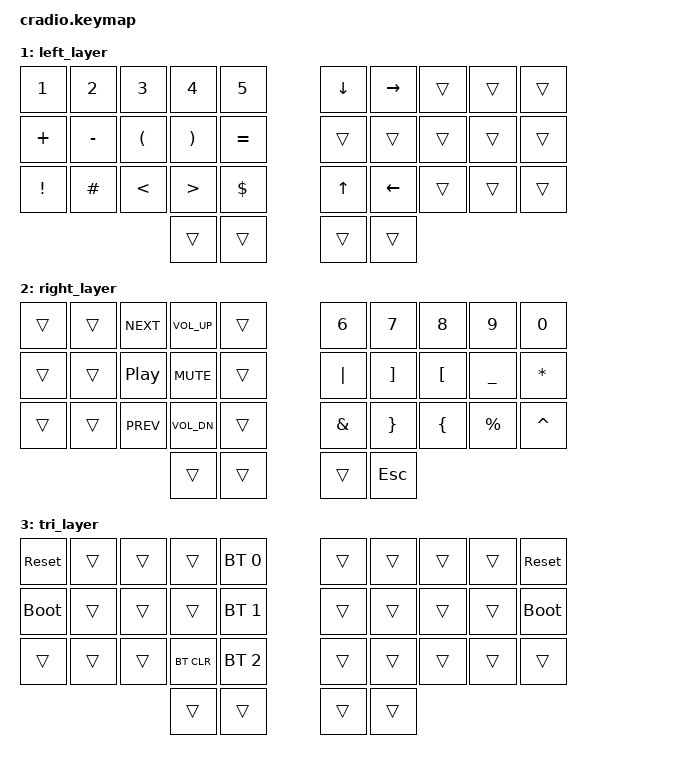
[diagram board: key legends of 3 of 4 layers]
// Copyright (c) 2022 The ZMK Contributors
// SPDX-License-Identifier: MIT

#include <behaviors.dtsi>
#include <dt-bindings/zmk/keys.h>
#include <dt-bindings/zmk/bt.h>

// Home row mods macro
#define HRML(k1,k2,k3,k4) &ht LGUI k1  &ht LALT k2  &ht LSHFT k3  &ht LCTRL k4
#define HRMR(k1,k2,k3,k4) &ht RCTRL k1  &ht RSHFT k2  &ht RALT k3  &ht RGUI k4

/ {
    behaviors {
        ht: hold_tap {
            label = "hold_tap";
            compatible = "zmk,behavior-hold-tap";
            #binding-cells = <2>;
            flavor = "tap-preferred";
            tapping-term-ms = <220>;
            quick-tap-ms = <75>;
            require-prior-idle-ms = <100>;
            bindings = <&kp>, <&kp>;
        };
    };

    conditional_layers {
        compatible = "zmk,conditional-layers";
        tri_layer {
            if-layers = <1 2>;
            then-layer = <3>;
        };
    };

    combos { 
        compatible = "zmk,combos";

        combo_esc {
            timeout-ms = <50>;
            key-positions = <0 31>;
            bindings = <&kp ESC>;
        };

        combo_bslh {
            timeout-ms = <50>;
            key-positions = <29 32>;
            bindings = <&kp BSLH>;
        };

        combo_btick {
            timeout-ms = <50>;
            key-positions = <20 31>;
            bindings = <&kp GRAVE>;
        };

        combo_quot {
            timeout-ms = <50>;
            key-positions = <19 32>;
            bindings = <&kp SQT>;
        };

        combo_at {
            timeout-ms = <25>;
            key-positions = <10 13>;
            bindings = <&kp AT>;
        };

    };

    keymap {
        compatible = "zmk,keymap";
        default_layer {
            bindings = <
        //╭──────────┬──────────┬──────────┬──────────┬──────────╮   ╭──────────┬──────────┬──────────┬──────────┬──────────╮
        //│  Q       │  W       │  F       │  P       │  B       │   │  J       │  L       │  U       │  Y       │  ;       │
            &kp Q      &kp W      &kp F      &kp P      &kp B          &kp J      &kp L      &kp U      &kp Y      &kp SEMI
        //├──────────┼──────────┼──────────┼──────────┼──────────┤   ├──────────┼──────────┼──────────┼──────────┼──────────┤
        //│  A       │  R       │  S       │  T       │  G       │   │  M       │  N       │  E       │  I       │  O       │
            HRML(A,        R,         S,         T)     &kp G          &kp M      HRMR(N,        E,         I,        O)
        //├──────────┼──────────┼──────────┼──────────┼──────────┤   ├──────────┼──────────┼──────────┼──────────┼──────────┤
        //│  Z       │  X       │  C       │  D       │  V       │   │  K       │  H       │ , <      │ . >      │ / ?      │
            &kp Z      &kp X      &kp C      &kp D      &kp V          &kp K      &kp H      &kp COMMA  &kp DOT    &kp FSLH
        //╰──────────┴──────────┴──────────┼──────────┼──────────┤   ├──────────┼──────────┼──────────┴──────────┴──────────╯
                                            &lt 2 TAB  &kp SPACE      &kp BSPC   &lt 1 ENTER
        //                                 ╰──────────┴──────────╯   ╰──────────┴──────────╯
            >;
        };

        left_layer {
            bindings = <
        //╭──────────┬──────────┬──────────┬──────────┬──────────╮   ╭──────────┬──────────┬──────────┬──────────┬──────────╮
        //│   1      │  2       │  3       │  4       │  5       │   │          │          │          │          │          │
            &kp N1    &kp N2     &kp N3     &kp N4     &kp N5         &kp DOWN   &kp RIGHT  &trans     &trans     &trans
        //├──────────┼──────────┼──────────┼──────────┼──────────┤   ├──────────┼──────────┼──────────┼──────────┼──────────┤
        //│  +       │  -       │  (       │  )       │  =       │   │          │          │          │          │          │
            &kp PLUS  &kp MINUS  &kp LPAR   &kp RPAR   &kp EQUAL      &trans     &trans     &trans     &trans     &trans
        //├──────────┼──────────┼──────────┼──────────┼──────────┤   ├──────────┼──────────┼──────────┼──────────┼──────────┤
        //│  !       │  #       │  <       │  >       │  $       │   │          │          │          │          │          │
            &kp EXCL   &kp HASH  &kp LT     &kp GT     &kp DLLR       &kp UP    &kp LEFT    &trans     &trans     &trans
        //╰──────────┴──────────┴──────────┼──────────┼──────────┤   ├──────────┼──────────┼──────────┴──────────┴──────────╯
                                             &trans     &trans        &trans     &trans
        //                                 ╰──────────┴──────────╯   ╰──────────┴──────────╯
            >;
        };

        right_layer {
            bindings = <
        //╭──────────┬──────────┬──────────┬──────────┬──────────╮   ╭──────────┬──────────┬──────────┬──────────┬──────────╮
        //│          │          │          │          │          │   │  6       │  7       │  8       │   9      │  0       │
           &trans     &trans     &kp C_NEXT &kp C_VOL_UP &trans       &kp N6     &kp N7     &kp N8     &kp N9    &kp N0
        //├──────────┼──────────┼──────────┼──────────┼──────────┤   ├──────────┼──────────┼──────────┼──────────┼──────────┤
        //│          │          │          │          │          │   │  |       │  ]       │  [       │  _       │  *       │
           &trans     &trans     &kp C_PP   &kp C_MUTE   &trans       &kp PIPE   &kp RBKT   &kp LBKT   &kp UNDER  &kp STAR
        //├──────────┼──────────┼──────────┼──────────┼──────────┤   ├──────────┼──────────┼──────────┼──────────┼──────────┤
        //│          │          │          │          │          │   │  &       │  }       │  {       │  %       │  ^       │
           &trans     &trans     &kp C_PREV &kp C_VOL_DN &trans       &kp AMPS   &kp RBRC   &kp LBRC   &kp PRCNT  &kp CARET
        //╰──────────┴──────────┴──────────┼──────────┼──────────┤   ├──────────┼──────────┼──────────┴──────────┴──────────╯
                                            &trans     &trans         &trans     &kp ESC
        //                                 ╰──────────┴──────────╯   ╰──────────┴──────────╯
            >;
        };

        tri_layer {
            bindings = <
        //╭──────────┬──────────┬──────────┬──────────┬──────────╮   ╭──────────┬──────────┬──────────┬──────────┬──────────╮
        //│ RESET    │          │          │          │PROFILE 0 │   │          │          │          │          │  RESET   │
           &sys_reset  &trans     &trans     &trans    &bt BT_SEL 0    &trans     &trans     &trans     &trans    &sys_reset
        //├──────────┼──────────┼──────────┼──────────┼──────────┤   ├──────────┼──────────┼──────────┼──────────┼──────────┤
        //│BOOTLOADER│          │          │          │PROFILE 1 │   │          │          │          │          │BOOTLOADER│
          &bootloader  &trans     &trans     &trans    &bt BT_SEL 1    &trans     &trans     &trans     &trans    &bootloader
        //├──────────┼──────────┼──────────┼──────────┼──────────┤   ├──────────┼──────────┼──────────┼──────────┼──────────┤
        //│          │          │          │ CLEAR BT │PROFILE 2 │   │          │          │          │          │          │
            &trans     &trans     &trans    &bt BT_CLR &bt BT_SEL 2    &trans     &trans     &trans     &trans     &trans
        //╰──────────┴──────────┴──────────┼──────────┼──────────┤   ├──────────┼──────────┼──────────┴──────────┴──────────╯
                                             &trans     &trans         &trans     &trans
        //                                 ╰──────────┴──────────╯   ╰──────────┴──────────╯
            >;
        };
    };
};
